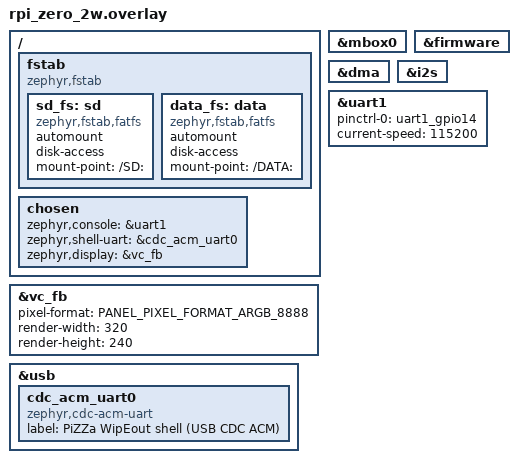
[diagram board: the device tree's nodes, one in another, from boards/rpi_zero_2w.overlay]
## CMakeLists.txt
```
# SPDX-License-Identifier: AGPL-3.0-or-later
#
# PiZZa -- WipEout demo. Stand-alone Zephyr application that links the
# phoboslab/wipeout-rewrite engine (software renderer) against the
# rpi_zero_2w board and presents 320x240 frames to the BCM2835
# VideoCore HDMI framebuffer via HVS hardware scaling.
#
# The engine source lives outside the PiZZa repo at
# ~/github/wipeout-rewrite. The port preserves the upstream tree --
# zero edits -- by:
#
#   1. Replacing src/render_software.c with our SMP-patched copy
#      (the upstream file is excluded from COMMON_SRC below).
#   2. Replacing src/platform_*.c with src/platform_zephyr.c.
#   3. --wrap=file_exists / file_load / file_store on the engine's
#      libc-backed utils.c so SD-card I/O lands on Zephyr's fs_*
#      with a /SD: prefix instead of POSIX fopen() (which is not
#      wired to FATFS in this image).
#
# The renderer is AGPL-3.0-or-later (matching wipeout-rewrite). The
# rest of PiZZa is Apache-2.0; this binary is AGPL by virtue of
# linking the engine, same model as the Jet demo.

cmake_minimum_required(VERSION 3.20.0)

find_package(Zephyr REQUIRED HINTS $ENV{ZEPHYR_BASE})
project(pizza-wipeout C)

# Pull in the sample usbd helper (sample_usbd_init_device + sample_usbd.h)
# the same way PizzaShell / Jet do. Only needed when the USB device
# stack is in the build; rpi_zero_2w turns it on.
if(CONFIG_USB_DEVICE_STACK_NEXT)
  include(${ZEPHYR_BASE}/samples/subsys/usb/common/common.cmake)
endif()

if(NOT DEFINED WIPEOUT_SRC_DIR)
  set(WIPEOUT_SRC_DIR "$ENV{HOME}/github/wipeout-rewrite/src")
endif()
if(NOT EXISTS "${WIPEOUT_SRC_DIR}/render_software.c")
  message(FATAL_ERROR
    "wipeout-rewrite sources not found at ${WIPEOUT_SRC_DIR}. Clone "
    "https://github.com/phoboslab/wipeout-rewrite and either keep it "
    "at ~/github/wipeout-rewrite or pass -DWIPEOUT_SRC_DIR=<path>.")
endif()

# Upstream engine sources (everything in src/ except the host platform
# backends and the original render_software.c -- we ship our own).
set(WIPEOUT_COMMON_SRC
  ${WIPEOUT_SRC_DIR}/utils.c
  ${WIPEOUT_SRC_DIR}/types.c
  ${WIPEOUT_SRC_DIR}/system.c
  ${WIPEOUT_SRC_DIR}/mem.c
  ${WIPEOUT_SRC_DIR}/input.c
  ${WIPEOUT_SRC_DIR}/wipeout/race.c
  ${WIPEOUT_SRC_DIR}/wipeout/camera.c
  ${WIPEOUT_SRC_DIR}/wipeout/object.c
  ${WIPEOUT_SRC_DIR}/wipeout/droid.c
  ${WIPEOUT_SRC_DIR}/wipeout/ui.c
  ${WIPEOUT_SRC_DIR}/wipeout/hud.c
  ${WIPEOUT_SRC_DIR}/wipeout/image.c
  ${WIPEOUT_SRC_DIR}/wipeout/game.c
  ${WIPEOUT_SRC_DIR}/wipeout/menu.c
  ${WIPEOUT_SRC_DIR}/wipeout/main_menu.c
  ${WIPEOUT_SRC_DIR}/wipeout/ingame_menus.c
  ${WIPEOUT_SRC_DIR}/wipeout/title.c
  ${WIPEOUT_SRC_DIR}/wipeout/intro.c
  ${WIPEOUT_SRC_DIR}/wipeout/scene.c
  ${WIPEOUT_SRC_DIR}/wipeout/ship.c
  ${WIPEOUT_SRC_DIR}/wipeout/ship_ai.c
  ${WIPEOUT_SRC_DIR}/wipeout/ship_player.c
  ${WIPEOUT_SRC_DIR}/wipeout/track.c
  ${WIPEOUT_SRC_DIR}/wipeout/weapon.c
  ${WIPEOUT_SRC_DIR}/wipeout/particle.c
  ${WIPEOUT_SRC_DIR}/wipeout/sfx.c
)

# Port sources. The rasteriser file is picked by Kconfig:
#   CONFIG_WIPEOUT_RENDERER_SMP (default) -> render_software_smp.c,
#     the upstream renderer with the band edit applied + gfx_parallel_run
#     wiring.
#   CONFIG_WIPEOUT_RENDERER_PIZZA -> render_software_pizza.c, the
#     Q16/RGB565 rewrite (scaffolding only; see
#     notes/wipeout_pizza_renderer_spec.md).
# gfx_parallel_zephyr.c is the persistent worker pool (band 0 on
# caller); platform_zephyr.c is the platform.h backend + the Zephyr
# main thread that drives the game loop; wipeout_glue.c wraps the
# engine's file_* helpers onto Zephyr fs_* + /SD: prefix.
if(CONFIG_WIPEOUT_RENDERER_PIZZA)
  set(WIPEOUT_RENDERER_SRC src/render_software_pizza.c)
else()
  set(WIPEOUT_RENDERER_SRC src/render_software_smp.c)
endif()

set(WIPEOUT_PORT_SRC
  ${WIPEOUT_RENDERER_SRC}
  src/gfx_parallel_zephyr.c
  src/platform_zephyr.c
  src/wipeout_glue.c
)

target_sources(app PRIVATE
  ${WIPEOUT_COMMON_SRC}
  ${WIPEOUT_PORT_SRC}
)

# Engine headers (#include "platform.h", "render.h", etc. without
# subdirs) and its bundled stb / pl_mpeg / qoa.
target_include_directories(app PRIVATE
  ${WIPEOUT_SRC_DIR}
  ${WIPEOUT_SRC_DIR}/libs
  src
)

target_compile_definitions(app PRIVATE
  RENDERER_SOFTWARE=1
)

# Loosen the warnings the engine trips with -Werror'ish defaults --
# upstream builds with -Wno-unused-variable and uses 1.0/255.0 idioms
# the compiler can't always prove safe.
target_compile_options(app PRIVATE
  -Wno-unused-variable
  -Wno-unused-but-set-variable
  -Wno-missing-braces
  -Wno-incompatible-pointer-types
)

# Redirect the engine's libc-backed file helpers to our Zephyr fs_*
# implementations. The originals stay in utils.c (unused at link time
# after wrapping) so no upstream edit is needed.
# PUBLIC, not PRIVATE: app is a Zephyr-built static lib, so PRIVATE
# link options never reach the final ELF link. PUBLIC propagates them
# through the target's INTERFACE_LINK_OPTIONS to the parent.
target_link_options(app PUBLIC
  -Wl,--wrap=file_exists
  -Wl,--wrap=file_load
  -Wl,--wrap=file_store
)
```

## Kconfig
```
# SPDX-License-Identifier: AGPL-3.0-or-later
#
# Pull in the SAMPLE_USBD_* options used by sample_usbd_init.c on
# boards that build the USB device stack. Same pattern PizzaShell /
# Jet use.

source "samples/subsys/usb/common/Kconfig.sample_usbd"

# Which port-side rasteriser to compile. The SMP renderer is the
# shipping renderer; the PiZZa renderer is the in-development
# Q16-RGB565 rewrite per notes/wipeout_pizza_renderer_spec.md.
# Today's builds keep the SMP default; flipping the gate swaps in
# the new file.
choice
	prompt "Wipeout software renderer backend"
	default WIPEOUT_RENDERER_SMP
	help
	  Selects which renderer source file the wipeout port compiles.
	  Both files implement the same render.h API; only one is
	  linked into a given build.

config WIPEOUT_RENDERER_SMP
	bool "Float ARGB_8888 SMP renderer (shipping)"
	help
	  render_software_smp.c -- the upstream phoboslab renderer plus
	  the PiZZa SMP band edits. Shipping configuration. ARGB_8888
	  framebuffer, float-per-pixel inner loop, scanline rasteriser.

config WIPEOUT_RENDERER_PIZZA
	bool "Q16 RGB565 PiZZa renderer (in development)"
	help
	  render_software_pizza.c -- Q16 fixed-point inner loop, RGB565
	  framebuffer, split RGBA5551 + RGBA4444 atlases, edge-function
	  rasteriser with five specialised fast paths. Targets ~3-5x
	  speedup over the SMP renderer on rpi_zero_2w.

	  Currently scaffolding only; enabling this option builds and
	  links but renders a black screen. See
	  notes/wipeout_pizza_renderer_spec.md for the phased plan.

endchoice

config WIPEOUT_USE_QPU_TRANSFORM
	bool "Use V3D QPU for vec3_transform_perspective (EMPIRICALLY SLOWER)"
	default n
	depends on WIPEOUT_RENDERER_SMP
	select BCM2835_V3D
	help
	  Offload the per-frame vec3_transform_perspective vertex math
	  from the A53 onto the BCM2710 V3D QPUs.

	  *** EMPIRICALLY NET-NEGATIVE -- DEFAULT OFF FOR A REASON ***

	  Standalone the QPU is ~9x faster per vertex than scalar
	  (48 ns vs 445 ns; see samples/drivers/bcm2835_v3d/vec3_xform).
	  But wipeout's renderer hands tris in 3-vert chunks, forcing
	  per-tri staging into V3D coherent memory + per-flush scatter/
	  gather. Measured via `wipeout bench all` (2026-06-09 on
	  rpi_zero_2w, NUM_QPUS=12, Normal-NC mapping + DSB barriers,
	  fused scatter, MIN_TRIS_FOR_KICK=64):

	    config                  scalar   QPU      delta
	    parallel-4  1000t / 1m   5753us  9205us   1.60x slower
	    parallel-4  3000t / 3m  14127us 24578us   1.74x slower
	    parallel-4  5000t / 3m  22589us 40088us   1.77x slower
	    parallel-4  7000t / 3m  30981us 55456us   1.79x slower

	  Per-tri the QPU integration costs ~3.5 us of staging +
	  finalize + scatter/gather overhead, displacing only ~1.3 us
	  of scalar transform (3 verts * 445 ns). The arithmetic does
	  not work out at this batching granularity -- no incremental
	  fix (drop AoS staging ~500 us/frame, bucket-on-stage
	  ~100 us/frame) closes the multi-millisecond gap.

	  Where the QPU genuinely wins on this silicon: single big-
	  batch kernels in the thousands+ of items (FFT, image filters,
	  small-model inference). Per-frame vertex transform in a
	  3-vert-at-a-time renderer is the wrong shape.

	  Enable only for code-path experimentation; the renderer falls
	  back to scalar for batches smaller than 64 triangles and on
	  QPU failure, so output is always correct (~16 ULP from
	  scalar, sub-pixel on a 240p framebuffer). The performance
	  cost is real and visible.

source "Kconfig.zephyr"
```

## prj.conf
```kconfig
# SPDX-License-Identifier: AGPL-3.0-or-later
#
# Common config for the PiZZa WipEout demo. Per-board overrides
# (display, USB, storage, SMP) live in boards/<board>.conf.

CONFIG_PRINTK=y
CONFIG_BOOT_BANNER=y

# Keep printk() synchronous so the engine's heavy boot-time logging
# (track scan, ship load) lands on the console even when the render
# loop is busy. Same reasoning as the Jet demo.
CONFIG_LOG_PRINTK=n

# picolibc's errno needs TLS. The cross-compile toolchain doesn't
# advertise TLS by default; opt in. Without this, errno writes off
# the main thread silently scribble through a wild TPIDRRO_EL0
# offset (the symptom is a Hard Fault on the first failing fs_open
# or fs_stat call).
CONFIG_TOOLCHAIN_CROSS_COMPILE_SUPPORTS_THREAD_LOCAL_STORAGE=y
CONFIG_THREAD_LOCAL_STORAGE=y

# Heap budgets. The engine uses its own bump allocator (mem.c) for
# assets but routes a handful of allocations through libc malloc:
# pl_mpeg's video frame buffer (skipped here -- no intro.mpeg),
# realloc() in render_software's depth buffer, qsort scratch. 1 MiB
# is plenty for the depth/zbuffer and per-flush sort scratch.
CONFIG_COMMON_LIBC_MALLOC_ARENA_SIZE=1048576

# Engine asset model. The bump arena lives in BSS at link time
# (mem.c MEM_HUNK_BYTES); we leave that at its upstream default but
# bump MAIN_STACK because game_init has deep call chains.
CONFIG_MAIN_STACK_SIZE=16384
CONFIG_FPU=y
CONFIG_STACK_SENTINEL=y
CONFIG_ASSERT=y
```

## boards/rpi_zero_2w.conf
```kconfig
# SPDX-License-Identifier: AGPL-3.0-or-later
#
# Raspberry Pi Zero 2 W (BCM2710, Cortex-A53, AArch64) -- WipEout demo.
# Console + logs on the mini-UART. USB CDC ACM shell for the `wipeout`
# command set (clock check, fps, frame capture). 4-core SMP enabled
# via the local Zephyr `dev` branch (smp-base..dev range -- the
# SOC_PER_CORE_INIT_HOOK gate plus the BCM2836 mailbox-0 sched-IPI
# driver). `wipeout flush parallel 4 64` runs bands 1..3 on their
# own cpus.

CONFIG_BOOT_DELAY=200

# 4-core SMP. Brings up cpu@1..3 via spin-table secondary release;
# scheduler IPI runs over the BCM2836 per-core mailbox 0. Peripheral
# and GPU interrupts stay on core 0 -- fine for the renderer because
# workers wait on semaphores from cpu 0 and do no peripheral I/O.
# Enables k_thread_cpu_pin() so gfx_parallel_zephyr.c's pin path
# actually puts bands 1..3 on cpus 1..3.
CONFIG_SMP=y
CONFIG_MP_MAX_NUM_CPUS=4
CONFIG_SCHED_CPU_MASK=y
CONFIG_SCHED_CPU_MASK_PIN_ONLY=y
CONFIG_PM_CPU_OPS=y
CONFIG_PM_CPU_OPS_SPINTABLE=y
# FPU_SHARING rides the Cortex-A Kconfig imply: the FPU-flush IPI runs
# as mailbox-0 bit 1 next to the scheduler IPI (zephyr dev a036e77bc0f),
# so FPU context migrates safely between cores. This is the gate for
# NEON in the rasteriser -- V registers alias the FP register file.

# VC mailbox + firmware (framebuffer alloc chain, ARM clock readback,
# die temp).
CONFIG_RASPBERRYPI_FIRMWARE=y
CONFIG_HWINFO=y
CONFIG_SENSOR=y

# HDMI display via VC firmware FB. ARGB_8888 (depth 32) so the engine's
# rgba_t buffer maps 1:1 onto a 32-bit FB word (modulo the R/B swap
# we do at present time -- see platform_zephyr.c). Pair with the
# render-width / render-height overlay for HVS 320x240 -> monitor
# scaling.
CONFIG_DISPLAY=y
CONFIG_BCM2835_FB=y

# BCM2835 DMA -- the FB driver claims a free channel at init for the
# backbuffer->fb blit. Hides the present memcpy off the CPU.
CONFIG_DMA=y
CONFIG_DMA_BCM2835=y

# Storage stack on the external microSD slot (SDHost). Wipeout assets
# (~150 MB after `wipeout-data-v01.zip` extraction) live at
# /SD:/wipeout/. CONFIG_FILE_SYSTEM_MKFS stays OFF -- a failed mount
# must not erase the user's card.
CONFIG_DISK_ACCESS=y
CONFIG_DISK_DRIVERS=y
CONFIG_SDMMC_SUBSYS=y
CONFIG_FILE_SYSTEM=y
CONFIG_FAT_FILESYSTEM_ELM=y
CONFIG_FS_FATFS_LFN=y
CONFIG_FS_FATFS_FSTAB_AUTOMOUNT=y
CONFIG_FILE_SYSTEM_MKFS=n
CONFIG_FS_FATFS_MOUNT_MKFS=n

# Multi-partition support. The PINN-imaged SD has a RECOVERY FAT at
# partition 1 (Pi firmware, dtbs, our kernel.img -- bootloader-visible
# only, no room for assets). We mount that as /SD: AND also bind a
# second FAT partition (partition 2, manually added from the ~31 GiB
# of unallocated tail on the card) as /DATA: for the wipeout/ asset
# tree. Both logical volumes share the one physical SDHost disk;
# FatFs reads the MBR to locate each partition's LBA range via the
# app-side VolToPart[] table in wipeout_glue.c.
CONFIG_FS_FATFS_MULTI_PARTITION=y
CONFIG_FS_FATFS_CUSTOM_MOUNT_POINT_COUNT=2
CONFIG_FS_FATFS_CUSTOM_MOUNT_POINTS="SD,DATA"

# USB device stack -- CDC ACM as the shell endpoint, matching the
# rest of PiZZa. Boards with USBD need the sample helper.
CONFIG_USB_DEVICE_STACK_NEXT=y
CONFIG_UDC_DWC2=y
CONFIG_UDC_DWC2_DMA=n
CONFIG_SERIAL=y
CONFIG_USBD_CDC_ACM_CLASS=y
CONFIG_CDC_ACM_SERIAL_INITIALIZE_AT_BOOT=n
CONFIG_SAMPLE_USBD_PRODUCT="PiZZa WipEout demo -- rpi_zero_2w"
CONFIG_SAMPLE_USBD_MANUFACTURER="jetpax/PiZZa"
CONFIG_SAMPLE_USBD_PID=0xCAFE
CONFIG_USBD_THREAD_STACK_SIZE=4096
CONFIG_UDC_DWC2_STACK_SIZE=4096

# Interactive shell over the USB CDC line (boot logs stay on the
# mini-UART). The `wipeout` subcommand set is registered from
# platform_zephyr.c.
CONFIG_SHELL=y
CONFIG_SHELL_BACKEND_SERIAL=y
CONFIG_KERNEL_SHELL=y
CONFIG_SHELL_STACK_SIZE=8192
CONFIG_SHELL_VT100_COMMANDS=y
CONFIG_SHELL_HISTORY=y
CONFIG_SHELL_TAB=y
CONFIG_SHELL_LOG_BACKEND=n

# Logging on the board console (mini-UART), off the shell prompt.
CONFIG_LOG=y
CONFIG_LOG_BUFFER_SIZE=16384
CONFIG_LOG_BACKEND_UART=y
CONFIG_LOG_MODE_DEFERRED=y
CONFIG_USBD_CDC_ACM_LOG_LEVEL_WRN=y
CONFIG_USBD_LOG_LEVEL_INF=y
CONFIG_UDC_DRIVER_LOG_LEVEL_WRN=y
```

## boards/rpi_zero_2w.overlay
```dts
/*
 * SPDX-License-Identifier: AGPL-3.0-or-later
 *
 * PiZZa WipEout demo overlay for rpi_zero_2w.
 *
 *   - &mbox0 + &firmware: VC mailbox + property tags (FB alloc,
 *     clock readback, temp).
 *   - &vc_fb: HDMI framebuffer at the monitor's native scanout
 *     resolution; the engine paints into a 320x240 virtual
 *     framebuffer and the VideoCore HVS hardware scaler upscales it
 *     to the cable on the fly. Picks the PSX-style nostalgic look
 *     and keeps per-frame write bandwidth at 300 KiB instead of
 *     ~7 MiB at HDMI native.
 *   - &dma: BCM2835 DMA controller for the bcm2835_fb backbuffer
 *     blit (fast path).
 *   - &usb + cdc_acm child: USB CDC ACM as the interactive shell
 *     endpoint, same shape as PizzaShell.
 *   - SD fstab at /SD: (FATFS) for wipeout asset loading.
 *   - mini-UART (uart1) as console + LOG_* target, matching the
 *     PiZZa convention.
 */

#include <zephyr/dt-bindings/display/panel.h>

&mbox0 {
	status = "okay";
};

&firmware {
	status = "okay";
};

/*
 * BCM2835 DMA controller -- bcm2835_fb requests a free channel at
 * init for its backbuffer->fb blit. No DT wiring on the FB side.
 */
&dma {
	status = "okay";
};

&vc_fb {
	/* No width / height: driver reads VC's EDID-negotiated scanout
	 * mode at boot (typically 1824x984 or whatever the monitor
	 * reports).
	 *
	 * render-width / render-height pin the virtual framebuffer the
	 * ARM side paints into. 320 x 240 = 76800 px = 300 KiB at 32 bpp.
	 * 320 * 4 = 1280 bytes = 64-byte aligned, so VC returns pitch ==
	 * row_bytes (no padding) and the FB driver's contiguous-DMA fast
	 * path engages. HVS scales 320x240 -> monitor native at 0 ARM
	 * cost.
	 */
	pixel-format = <PANEL_PIXEL_FORMAT_ARGB_8888>;
	render-width = <320>;
	render-height = <240>;
	status = "okay";
};

&i2s {
	/* No audio yet -- left enabled in case M7 lands later. */
	status = "okay";
};

/*
 * Auto-mount the external microSD slot as FAT at /SD: (FATFS volume
 * convention: the path after the leading '/' is the disk-access disk
 * name). The board DTS registers the disk as "SD". The user extracts
 * wipeout-data-v01.zip to /SD:/wipeout/ before flashing.
 *
 * Format-on-mount-fail safety: CONFIG_FILE_SYSTEM_MKFS and
 * CONFIG_FS_FATFS_MOUNT_MKFS are both off in boards/rpi_zero_2w.conf,
 * so a failed mount cannot accidentally erase the user's SD card.
 */
/ {
	fstab {
		compatible = "zephyr,fstab";

		/* PINN RECOVERY (FAT) -- Pi firmware + dtbs + kernel.img.
		 * Save data (small) writes go here. Mount string "/SD:"
		 * matches CONFIG_FS_FATFS_CUSTOM_MOUNT_POINTS index 0,
		 * which VolToPart[] maps to physical drive 0, partition 1.
		 */
		sd_fs: sd {
			compatible = "zephyr,fstab,fatfs";
			automount;
			disk-access;
			mount-point = "/SD:";
		};

		/* User-created FAT partition (typically partition 3 on the
		 * PINN card) holding the wipeout/ asset tree extracted from
		 * wipeout-data-v01.zip. Mount string "/DATA:" matches
		 * CONFIG_FS_FATFS_CUSTOM_MOUNT_POINTS index 1, which
		 * VolToPart[] maps to physical drive 0, partition 3. Same
		 * physical SDHost as /SD: -- the partition split happens
		 * inside FatFs by reading the MBR.
		 */
		data_fs: data {
			compatible = "zephyr,fstab,fatfs";
			automount;
			disk-access;
			mount-point = "/DATA:";
		};
	};
};

&usb {
	status = "okay";

	cdc_acm_uart0: cdc_acm_uart0 {
		compatible = "zephyr,cdc-acm-uart";
		label = "PiZZa WipEout shell (USB CDC ACM)";
	};
};

/ {
	chosen {
		/* Boot logs + LOG_* on the mini-UART (uart1) at 115200 --
		 * needs config.txt `enable_uart=1`, NOT `dtoverlay=disable-bt`.
		 * Interactive shell on USB CDC ACM. HDMI is the engine
		 * display target (auto-detected through DT_HAS_CHOSEN by
		 * the FB driver).
		 */
		zephyr,console = &uart1;
		zephyr,shell-uart = &cdc_acm_uart0;
		zephyr,display = &vc_fb;
	};
};

/* Mini-UART (uart1) console setup. Same stanza PizzaShell carries --
 * the board DTS now defaults to PL011 @ 1 Mbaud, but PiZZa boards
 * keep the historical mini-UART path so a stock config.txt with
 * `enable_uart=1` (no disable-bt overlay) just works.
 */
&uart1 {
	pinctrl-names = "default";
	pinctrl-0 = <&uart1_gpio14>;
	status = "okay";
	current-speed = <115200>;
};
```

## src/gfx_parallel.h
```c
/* SPDX-License-Identifier: AGPL-3.0-or-later
 *
 * Persistent band-parallel barrier for the PiZZa software renderer.
 * Verified bit-identical to serial in simulation (4 bands; 0 / 76 800
 * pixels differ) -- the property that breaks in naive parallel
 * rasterizer rewrites holds: y-band ownership of disjoint framebuffer
 * + depth rows is lock-free and order-preserving because tris are
 * z-sorted ONCE on the caller before fan-out.
 *
 * Backend split:
 *   - Host (sim): pthreads.
 *   - Zephyr / on-board: persistent pool of CONFIG threads pinned to
 *     cores 1..N-1 (CONFIG_SMP + CONFIG_SCHED_CPU_MASK), with the
 *     caller (game thread) executing band 0 itself. Without SMP
 *     enabled at the board level, all bands fall back onto the calling
 *     core -- the band split still produces correct output but the
 *     workers contend for CPU0 and the speedup is <= 1.
 */
#ifndef GFX_PARALLEL_H
#define GFX_PARALLEL_H

#include <stdint.h>

#define GFX_PARALLEL_MAX_BANDS 4

/* Runs fn(ctx, band_index) on `nbands` workers and blocks until all
 * finish. Caller thread runs band 0 inline.
 */
typedef void (*gfx_band_fn)(void *ctx, int band);

void gfx_parallel_init(int nbands);
void gfx_parallel_run(gfx_band_fn fn, void *ctx, int nbands);

/* True iff Zephyr was built with CONFIG_SMP and at least 2 CPUs are
 * runnable. Set inside gfx_parallel_init() so the renderer can pick
 * the serial flush when SMP is absent without burning a barrier
 * round-trip.
 */
int gfx_parallel_smp_active(void);

#endif /* GFX_PARALLEL_H */
```

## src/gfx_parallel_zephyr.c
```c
/* SPDX-License-Identifier: AGPL-3.0-or-later
 *
 * Zephyr backend for the band-parallel barrier. Persistent worker
 * pool: bands 1..N-1 each have a dedicated CONFIG thread parked on a
 * "go" semaphore between flushes; band 0 runs on the caller (game
 * thread).
 *
 * The cpu_pin call below is guarded on CONFIG_SCHED_CPU_MASK. Without
 * it (the rpi_zero_2w default today) the workers compete with the
 * caller for CPU0 cooperatively -- the band split still produces a
 * correct frame but speedup vs serial is <= 1. The path is here so
 * the renderer code is single-shape across SMP and UP; flip the gate
 * in render_software_smp.c (or via shell `wipeout flush parallel`)
 * to actually exercise it when SMP lands.
 */

#include <zephyr/kernel.h>
#include "gfx_parallel.h"

#define WORKER_STACK 8192

static struct k_thread       threads[GFX_PARALLEL_MAX_BANDS];
static K_THREAD_STACK_ARRAY_DEFINE(stacks, GFX_PARALLEL_MAX_BANDS, WORKER_STACK);
static struct k_sem          go[GFX_PARALLEL_MAX_BANDS];
static struct k_sem          done;
static gfx_band_fn           cur_fn;
static void                 *cur_ctx;
static int                   n_bands;
static int                   smp_active;

static void worker(void *p0, void *p1, void *p2)
{
	int band = (int)(intptr_t)p0;

	ARG_UNUSED(p1);
	ARG_UNUSED(p2);

	for (;;) {
		k_sem_take(&go[band], K_FOREVER);
		cur_fn(cur_ctx, band);
		k_sem_give(&done);
	}
}

void gfx_parallel_init(int nbands)
{
	if (nbands < 1) {
		nbands = 1;
	}
	if (nbands > GFX_PARALLEL_MAX_BANDS) {
		nbands = GFX_PARALLEL_MAX_BANDS;
	}
	n_bands = nbands;
	k_sem_init(&done, 0, nbands);

#if defined(CONFIG_SMP) && defined(CONFIG_SCHED_CPU_MASK)
	smp_active = (arch_num_cpus() > 1) ? 1 : 0;
#else
	smp_active = 0;
#endif

	/* Band 0 runs on the calling thread; spawn workers for bands
	 * 1..n-1 and try to pin them, one per core. With SMP off the
	 * pin is a no-op and the workers serialize on CPU0; with SMP
	 * on, each band runs lock-free on its own core.
	 */
	for (int b = 1; b < nbands; b++) {
		k_sem_init(&go[b], 0, 1);
		k_tid_t t = k_thread_create(&threads[b], stacks[b], WORKER_STACK,
					    worker, (void *)(intptr_t)b, NULL, NULL,
					    K_PRIO_COOP(5), 0, K_NO_WAIT);
		k_thread_name_set(t, "gfx_band");
#if defined(CONFIG_SMP) && defined(CONFIG_SCHED_CPU_MASK)
		(void)k_thread_cpu_pin(t, b);
#endif
	}
}

void gfx_parallel_run(gfx_band_fn fn, void *ctx, int nbands)
{
	if (nbands <= 1) {
		fn(ctx, 0);
		return;
	}
	if (nbands > n_bands) {
		nbands = n_bands;
	}
	cur_fn = fn;
	cur_ctx = ctx;
	for (int b = 1; b < nbands; b++) {
		k_sem_give(&go[b]);
	}
	fn(ctx, 0);
	for (int b = 1; b < nbands; b++) {
		k_sem_take(&done, K_FOREVER);
	}
}

int gfx_parallel_smp_active(void)
{
	return smp_active;
}
```

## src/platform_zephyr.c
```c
/* SPDX-License-Identifier: AGPL-3.0-or-later
 *
 * PiZZa WipEout port -- platform.h backend + Zephyr boot wiring.
 *
 * Architecture (locked):
 *   - RENDERER=SOFTWARE (pure C); engine renders into a 320x240
 *     rgba_t backbuffer in cached RAM.
 *   - HVS hardware scaling: vc_fb DT exposes render-width=320,
 *     render-height=240. VC upscales every frame to the monitor's
 *     EDID-negotiated native mode at zero ARM cost.
 *   - Present: byte-swap-in-place (engine rgba_t bytes are R,G,B,A;
 *     VC ARGB_8888 expects B,G,R,A in memory) then async DMA blit.
 *   - SD card auto-mounted at /SD: (FATFS); assets at /SD:/wipeout/.
 *   - Audio + BT HID out of scope this milestone.
 *
 * The Zephyr boot model is platform-calls-you: main() does board
 * bring-up, then either runs the game loop on the main thread or
 * (here) spawns a dedicated render thread. The shell's USB CDC
 * service keeps running on the system workqueue; the render thread
 * yields once per frame so the shell stays responsive.
 */

#include <zephyr/kernel.h>
#include <zephyr/device.h>
#include <zephyr/devicetree.h>
#include <zephyr/drivers/display.h>
#include <zephyr/drivers/display/bcm2835_fb.h>
#include <zephyr/shell/shell.h>
#include <zephyr/sys/printk.h>
#include <zephyr/logging/log.h>
#include <zephyr/fs/fs.h>
#include <stdint.h>
#include <stdio.h>
#include <string.h>

#include <rpi_fw.h>

#if IS_ENABLED(CONFIG_USB_DEVICE_STACK_NEXT)
#include <zephyr/usb/usbd.h>
#include <sample_usbd.h>
#endif

/* Engine headers. types.h pulls in stdint/math; platform.h declares
 * the 12-function contract this file implements; render.h gives us
 * vec2i_t, render_resolution_t, render_set_resolution, etc.; system.h
 * the system_init/system_update entry points.
 */
#include "types.h"
#include "platform.h"
#include "render.h"
#include "input.h"
#include "system.h"

LOG_MODULE_REGISTER(pizza_wipeout, LOG_LEVEL_INF);

/* Renderer parallel-flush knob (defined in render_software_smp.c).
 * Not in render.h -- it's a port-private switch the M5 benchmark
 * shell command toggles.
 */
extern void render_software_set_parallel(int enabled, int bands, int threshold);
extern int  render_software_get_parallel_bands(void);

/* ------------------------------------------------------------------ *
 *  Display state
 * ------------------------------------------------------------------ */

#define PIZZA_W 320
#define PIZZA_H 240
#define PIZZA_PX (PIZZA_W * PIZZA_H)

/* 64-byte aligned: DMA fast path + cache-line clean range. Size is
 * exactly 4800 cache lines so sys_cache_data_flush_range covers
 * nothing outside this buffer.
 */
static rgba_t pizza_backbuf[PIZZA_PX] __aligned(64);

static const struct device *pizza_display;
static int pizza_display_ready;

/* ------------------------------------------------------------------ *
 *  platform.h timing / window backend
 * ------------------------------------------------------------------ */

double platform_now(void)
{
	return (double)k_uptime_get() / 1000.0;
}

vec2i_t platform_screen_size(void)
{
	return (vec2i_t){PIZZA_W, PIZZA_H};
}

bool platform_get_fullscreen(void) { return true; }
void platform_set_fullscreen(bool on) { (void)on; }

void platform_exit(void)
{
	printk("[wipeout] platform_exit -- halting\n");
	k_fatal_halt(0);
}

/* ------------------------------------------------------------------ *
 *  platform.h audio backend (silent stub)
 * ------------------------------------------------------------------ */

static void (*pizza_audio_cb)(float *, uint32_t);

void platform_set_audio_mix_cb(void (*cb)(float *, uint32_t))
{
	pizza_audio_cb = cb;
	/* TODO(board): drive cb from an I2S DMA buffer-complete handler. */
}

/* ------------------------------------------------------------------ *
 *  platform.h screenbuffer backend (software renderer)
 *
 *  render_software calls this once per render_frame_prepare() to
 *  grab the destination pointer and byte-pitch. We hand back our
 *  cached rgba_t backbuffer; bytes are R,G,B,A in memory. The engine
 *  paints into it serial or banded (see render_software_smp.c).
 * ------------------------------------------------------------------ */

rgba_t *platform_get_screenbuffer(int32_t *pitch_bytes)
{
	*pitch_bytes = (int32_t)(PIZZA_W * sizeof(rgba_t));
	return pizza_backbuf;
}

/* ------------------------------------------------------------------ *
 *  platform.h asset backend
 *
 *  platform_open_asset returns a stdio FILE*; this firmware does NOT
 *  wire fopen to FATFS (no POSIX fs shim), so we return NULL. The
 *  only direct callers are sfx music streaming (graceful: empty
 *  music) and intro.mpeg (graceful: skips straight to TITLE).
 *
 *  platform_load_asset / platform_load_userdata route through the
 *  engine's file_load helper, which is --wrap'd to our fs_*-backed
 *  __wrap_file_load in wipeout_glue.c.
 * ------------------------------------------------------------------ */

#define PATH_PREFIX_ASSETS  ""              /* engine asks for "wipeout/foo" already */
#define PATH_PREFIX_USERDATA "userdata/"    /* save.dat etc. */

FILE *platform_open_asset(const char *name, const char *mode)
{
	(void)name; (void)mode;
	/* Streaming I/O not supported in this image. Callers that need
	 * a FILE* (sfx_music_open, intro.mpeg) handle NULL gracefully.
	 */
	return NULL;
}

uint8_t *platform_load_asset(const char *name, uint32_t *len)
{
	extern uint8_t *file_load(const char *path, uint32_t *bytes_read);
	return file_load(name, len);
}

uint8_t *platform_load_userdata(const char *name, uint32_t *len)
{
	extern bool file_exists(const char *path);
	extern uint8_t *file_load(const char *path, uint32_t *bytes_read);
	char path[128];

	snprintf(path, sizeof(path), "%s%s", PATH_PREFIX_USERDATA, name);
	if (!file_exists(path)) {
		*len = 0;
		return NULL;
	}
	return file_load(path, len);
}

uint32_t platform_store_userdata(const char *name, void *bytes, int32_t len)
{
	extern uint32_t file_store(const char *path, void *bytes, int32_t len);
	char path[128];

	snprintf(path, sizeof(path), "%s%s", PATH_PREFIX_USERDATA, name);
	return file_store(path, bytes, len);
}

/* ------------------------------------------------------------------ *
 *  USB CDC bring-up (boards with the USB device stack)
 * ------------------------------------------------------------------ */

#if IS_ENABLED(CONFIG_USB_DEVICE_STACK_NEXT)
static int pizza_usb_start(void)
{
	struct usbd_context *usbd = sample_usbd_init_device(NULL);

	if (usbd == NULL) {
		printk("[wipeout] sample_usbd_init_device failed\n");
		return -ENODEV;
	}
	if (!usbd_can_detect_vbus(usbd)) {
		int err = usbd_enable(usbd);
		if (err) {
			printk("[wipeout] usbd_enable failed: %d\n", err);
			return err;
		}
	}
	return 0;
}
/*
 * Bring CDC up at APPLICATION init, not from main(). The display + FATFS
 * (microSD) + SMP bring-up that runs during main() add enough latency
 * to push usbd_enable past macOS's USB enumeration retry window when
 * the mini-UART is connected at boot, which silently kills CDC on the
 * host side until the next replug. Running at APPLICATION captures
 * the enumeration window early; the rest of main() then runs while
 * the host completes descriptor exchange in parallel.
 */
SYS_INIT(pizza_usb_start, APPLICATION, CONFIG_APPLICATION_INIT_PRIORITY);
#else
static inline int pizza_usb_start(void) { return 0; }
#endif

/* ------------------------------------------------------------------ *
 *  Present: byte-swap-in-place + async DMA blit
 *
 *  Engine rgba_t bytes (R,G,B,A) don't match the VC ARGB_8888 layout
 *  (memory B,G,R,A). Swap byte[0] <-> byte[2] in the backbuffer; the
 *  next render_frame_prepare() clears the whole buffer, so the
 *  "wrong-order" state only persists from end-of-frame N until the
 *  start of frame N+1, never read by the renderer.
 *
 *  Pixel-loop walks rgba_t* (a 4-byte struct); on aarch64 with the
 *  buffer __aligned(64) the compiler vectorises this into LDR W /
 *  REV W / STR W pairs at ~one cycle per pixel.
 *
 *  Returns the wait+blit cycles for fps accounting.
 * ------------------------------------------------------------------ */

static void pizza_byteswap_inplace(rgba_t *buf, uint32_t pixels)
{
	uint8_t *b = (uint8_t *)buf;
	for (uint32_t i = 0; i < pixels; i++) {
		uint8_t r = b[0];
		b[0] = b[2];
		b[2] = r;
		b += 4;
	}
}

static int pizza_present(void)
{
	struct display_buffer_descriptor desc = {
		.buf_size = sizeof(pizza_backbuf),
		.width    = PIZZA_W,
		.height   = PIZZA_H,
		.pitch    = PIZZA_W,
		.frame_incomplete = false,
	};

	pizza_byteswap_inplace(pizza_backbuf, PIZZA_PX);

	/* display_write is synchronous: DMA fast path engages when
	 * width==virt_width and pitch==width (the case here -- 320 x 4 =
	 * 1280 is 64-byte aligned and VC returns no padding); the driver
	 * flushes the source cache range internally before kicking.
	 *
	 * We use the sync API instead of bcm2835_fb_write_async because
	 * we have a single backbuffer: an async kick from frame N would
	 * still be reading pizza_backbuf when frame N+1's
	 * render_frame_prepare() starts clearing it. Adding a second
	 * backbuffer would lift this restriction and let frame time
	 * approach max(render, blit) -- a clean future optimisation but
	 * not load-bearing for M4 (render dwarfs blit at 240p).
	 */
	return display_write(pizza_display, 0, 0, &desc, pizza_backbuf);
}

/* ------------------------------------------------------------------ *
 *  Game loop -- runs on a dedicated thread, owns the present step
 *
 *  system_update() internally calls render_frame_prepare ->
 *  game_update -> render_frame_end -> render_flush, leaving the
 *  finished frame in pizza_backbuf. We present afterwards.
 *
 *  fps and per-phase cycle counts are tracked here; the `wipeout`
 *  shell commands read these.
 * ------------------------------------------------------------------ */

#define GAME_STACK_SIZE 32768

K_THREAD_STACK_DEFINE(pizza_game_stack, GAME_STACK_SIZE);
static struct k_thread pizza_game_thread;

static volatile uint32_t pizza_fps_x100;   /* fps * 100, sampled every 1s */
static volatile uint32_t pizza_us_update;  /* avg per-frame system_update us */
static volatile uint32_t pizza_us_present; /* avg per-frame present us */
static volatile uint32_t pizza_frames_total;
static volatile uint32_t pizza_last_tris;

/* Flag set by shell `wipeout capture` to ask the loop to dump the
 * next finished frame to /SD:/wipeout-frame.ppm. Cleared after dump.
 */
static volatile int pizza_capture_requested;

extern int pizza_capture_frame(const rgba_t *buf, int w, int h);

extern void pizza_sd_diag(void);

static void pizza_game_loop(void *p1, void *p2, void *p3)
{
	ARG_UNUSED(p1);
	ARG_UNUSED(p2);
	ARG_UNUSED(p3);

	printk("[wipeout] game thread up; SD diagnostic:\n");
	pizza_sd_diag();
	printk("[wipeout] calling system_init\n");
	system_init();
	printk("[wipeout] system_init OK; entering render loop\n");

	int64_t fps_window_start = k_uptime_get();
	uint32_t frames_in_window = 0;
	uint64_t cyc_update = 0;
	uint64_t cyc_present = 0;
	const uint64_t cycles_per_sec = sys_clock_hw_cycles_per_sec();

	for (;;) {
		uint32_t c0 = k_cycle_get_32();
		system_update();
		uint32_t c1 = k_cycle_get_32();

		(void)pizza_present();
		uint32_t c2 = k_cycle_get_32();

		/* Capture happens BEFORE the next render_frame_prepare()
		 * clears the buffer. Note pizza_backbuf is currently
		 * byte-swapped (B,G,R,A); the capture helper inverts.
		 */
		if (pizza_capture_requested) {
			pizza_capture_requested = 0;
			pizza_capture_frame(pizza_backbuf, PIZZA_W, PIZZA_H);
		}

		cyc_update  += (uint32_t)(c1 - c0);
		cyc_present += (uint32_t)(c2 - c1);
		frames_in_window++;
		pizza_frames_total++;

		const render_stats_t *st = render_frame_get_stats();
		if (st) {
			pizza_last_tris = st->num_tris;
		}

		const int64_t now = k_uptime_get();
		const int64_t elapsed_ms = now - fps_window_start;
		if (elapsed_ms >= 1000) {
			pizza_fps_x100 =
				(uint32_t)((int64_t)frames_in_window * 100000 / elapsed_ms);
			pizza_us_update =
				(uint32_t)((cyc_update * 1000000U) /
					   (cycles_per_sec * frames_in_window));
			pizza_us_present =
				(uint32_t)((cyc_present * 1000000U) /
					   (cycles_per_sec * frames_in_window));
			printk("[wipeout] %u.%02u fps  update=%u us  present=%u us  tris=%u  bands=%d\n",
			       pizza_fps_x100 / 100, pizza_fps_x100 % 100,
			       pizza_us_update, pizza_us_present,
			       pizza_last_tris,
			       render_software_get_parallel_bands());
			fps_window_start = now;
			frames_in_window = 0;
			cyc_update = cyc_present = 0;
		}

		/* Cooperate with the shell + USBD + log thread. */
		k_yield();
	}
}

/* ------------------------------------------------------------------ *
 *  Shell command set: `wipeout <sub>`
 * ------------------------------------------------------------------ */

#define VC_CLOCK_ID_ARM  3U

static int cmd_wipeout_fps(const struct shell *sh, size_t argc, char **argv)
{
	ARG_UNUSED(argc); ARG_UNUSED(argv);
	shell_print(sh, "fps=%u.%02u  update=%u us  present=%u us",
		    pizza_fps_x100 / 100, pizza_fps_x100 % 100,
		    pizza_us_update, pizza_us_present);
	shell_print(sh, "tris/frame=%u  bands=%d  frames_total=%u",
		    pizza_last_tris,
		    render_software_get_parallel_bands(),
		    pizza_frames_total);
	return 0;
}

static int cmd_wipeout_clock(const struct shell *sh, size_t argc, char **argv)
{
	ARG_UNUSED(argc); ARG_UNUSED(argv);
	const struct device *fw = DEVICE_DT_GET_ONE(raspberrypi_bcm283x_firmware);
	uint32_t cur[2] = {VC_CLOCK_ID_ARM, 0};
	uint32_t max[2] = {VC_CLOCK_ID_ARM, 0};

	if (!device_is_ready(fw)) {
		shell_error(sh, "rpi_fw device not ready");
		return -ENODEV;
	}
	int e1 = rpi_fw_transfer(fw, RPI_FW_TAG_GET_CLOCK_RATE, cur, sizeof(cur));
	int e2 = rpi_fw_transfer(fw, RPI_FW_TAG_GET_MAX_CLOCK_RATE, max, sizeof(max));

	if (e1 < 0 || e2 < 0) {
		shell_error(sh, "rpi_fw clock query failed: cur=%d max=%d", e1, e2);
		return -EIO;
	}
	shell_print(sh, "ARM clock: cur=%u Hz  max=%u Hz", cur[1], max[1]);
	if (cur[1] < 900000000U) {
		shell_warn(sh, "ARM clock is below 900 MHz (got %u Hz). Set "
				"`arm_freq=1000` + `force_turbo=1` in config.txt to "
				"pin it at 1 GHz.", cur[1]);
	}
	return 0;
}

static int cmd_wipeout_flush(const struct shell *sh, size_t argc, char **argv)
{
	int bands = 4;
	int threshold = 64;

	if (argc < 2) {
		shell_print(sh, "usage: wipeout flush serial|parallel [bands] [threshold]");
		return -EINVAL;
	}
	if (strcmp(argv[1], "serial") == 0) {
		render_software_set_parallel(0, 1, 1);
		shell_print(sh, "render: serial flush");
		return 0;
	}
	if (strcmp(argv[1], "parallel") == 0) {
		extern int gfx_parallel_smp_active(void);

		if (argc >= 3) bands = atoi(argv[2]);
		if (argc >= 4) threshold = atoi(argv[3]);
		render_software_set_parallel(1, bands, threshold);
		shell_print(sh, "render: parallel flush bands=%d threshold=%d  (cpus=%u, smp_active=%d)",
			    bands, threshold,
			    (unsigned)arch_num_cpus(),
			    gfx_parallel_smp_active());
		if (!gfx_parallel_smp_active()) {
			shell_warn(sh, "SMP inactive: secondary cores didn't come up "
					"or build is UP. Workers will share CPU0 and pay "
					"barrier cost for no parallelism.");
		}
		return 0;
	}
	shell_error(sh, "unknown subcommand '%s'", argv[1]);
	return -EINVAL;
}

static int cmd_wipeout_capture(const struct shell *sh, size_t argc, char **argv)
{
	ARG_UNUSED(argc); ARG_UNUSED(argv);
	if (pizza_capture_requested) {
		shell_print(sh, "capture already pending");
		return 0;
	}
	pizza_capture_requested = 1;
	shell_print(sh, "capture armed: next frame -> /SD:/wipeout-frame.ppm");
	return 0;
}

static int cmd_wipeout_display(const struct shell *sh, size_t argc, char **argv)
{
	ARG_UNUSED(argc); ARG_UNUSED(argv);
	if (!pizza_display) {
		shell_error(sh, "display device unset");
		return -ENODEV;
	}
	struct display_capabilities caps;

	display_get_capabilities(pizza_display, &caps);
	shell_print(sh, "display: %ux%u px  fmt=0x%x  ready=%d",
		    caps.x_resolution, caps.y_resolution,
		    (unsigned)caps.current_pixel_format,
		    pizza_display_ready);
	return 0;
}

static int cmd_wipeout_smp(const struct shell *sh, size_t argc, char **argv)
{
	extern int gfx_parallel_smp_active(void);

	ARG_UNUSED(argc); ARG_UNUSED(argv);
	shell_print(sh, "CONFIG_SMP=%s  MP_MAX_NUM_CPUS=%d",
#ifdef CONFIG_SMP
		    "y",
#else
		    "n",
#endif
		    CONFIG_MP_MAX_NUM_CPUS);
	shell_print(sh, "arch_num_cpus() = %u  (cores ONLINE at runtime)",
		    (unsigned)arch_num_cpus());
	shell_print(sh, "gfx_parallel_smp_active() = %d  (renderer's worker-pool view)",
		    gfx_parallel_smp_active());
	return 0;
}

SHELL_STATIC_SUBCMD_SET_CREATE(sub_wipeout,
	SHELL_CMD(fps,     NULL, "Sampled fps + per-phase us",          cmd_wipeout_fps),
	SHELL_CMD(clock,   NULL, "VC ARM clock cur/max (Hz)",            cmd_wipeout_clock),
	SHELL_CMD(flush,   NULL, "serial | parallel [bands] [threshold]", cmd_wipeout_flush),
	SHELL_CMD(capture, NULL, "Dump next frame to /DATA:/wipeout-frame.ppm", cmd_wipeout_capture),
	SHELL_CMD(display, NULL, "Display capabilities + ready state",   cmd_wipeout_display),
	SHELL_CMD(smp,     NULL, "SMP build + runtime status",           cmd_wipeout_smp),
	SHELL_SUBCMD_SET_END
);
SHELL_CMD_REGISTER(wipeout, &sub_wipeout, "PiZZa WipEout demo control", NULL);

/* ------------------------------------------------------------------ *
 *  Zephyr main()
 * ------------------------------------------------------------------ */

int main(void)
{
	printk("\n[wipeout] PiZZa WipEout demo -- rpi_zero_2w SOFTWARE renderer\n");
	printk("[wipeout] SMP: arch_num_cpus()=%u  (MP_MAX_NUM_CPUS=%d)\n",
	       (unsigned)arch_num_cpus(), CONFIG_MP_MAX_NUM_CPUS);

	pizza_display = DEVICE_DT_GET(DT_CHOSEN(zephyr_display));
	if (!device_is_ready(pizza_display)) {
		printk("[wipeout] display device not ready -- HDMI not connected?\n");
		return -ENODEV;
	}

	struct display_capabilities caps;

	display_get_capabilities(pizza_display, &caps);
	pizza_display_ready = 1;
	printk("[wipeout] display %ux%u (HVS virt) fmt=0x%x\n",
	       caps.x_resolution, caps.y_resolution,
	       (unsigned)caps.current_pixel_format);

	if (caps.x_resolution != PIZZA_W || caps.y_resolution != PIZZA_H) {
		printk("[wipeout] WARNING: display reports %ux%u, expected %ux%u "
		       "(check render-width/render-height in overlay)\n",
		       caps.x_resolution, caps.y_resolution, PIZZA_W, PIZZA_H);
	}

	/* Spin the band-worker pool now (even on UP -- it's harmless and
	 * lets the render loop assume gfx_parallel_run is available).
	 * M5 benchmark switches between serial / parallel via the shell.
	 */
	extern void gfx_parallel_init(int nbands);
	gfx_parallel_init(4);

	k_thread_create(&pizza_game_thread, pizza_game_stack, GAME_STACK_SIZE,
			pizza_game_loop, NULL, NULL, NULL,
			K_PRIO_PREEMPT(1), 0, K_NO_WAIT);
	k_thread_name_set(&pizza_game_thread, "wipeout_game");

	/* main() returns; the game thread + shell continue. */
	return 0;
}
```

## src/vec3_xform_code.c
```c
#include "vec3_xform_code.h"

#ifdef __cplusplus
extern "C" {
#endif

#ifdef _MSC_VER
__declspec(align(8))
#elif defined(__GNUC__)
__attribute__((aligned(8)))
#endif
uint32_t vec3_xform_code[234] = {
0x15827d80, 0x10020027,
0x15827d80, 0x10020067,
0x15827d80, 0x100200a7,
0x15827d80, 0x100200e7,
0x15827d80, 0x10021027,
0x15827d80, 0x10021067,
0x15827d80, 0x100210a7,
0x15827d80, 0x100210e7,
0x15827d80, 0x10021127,
0x15827d80, 0x10021167,
0x15827d80, 0x100211a7,
0x15827d80, 0x100211e7,
0x15827d80, 0x10021227,
0x15827d80, 0x10021267,
0x15827d80, 0x100212a7,
0x15827d80, 0x100212e7,
0x15827d80, 0x10021327,
0x15827d80, 0x10021367,
0x15827d80, 0x100213a7,
0x15827d80, 0x100213e7,
0x15027d80, 0x10020127,
0x00000040, 0xe0021427,
0x81011000, 0xe00208a7,
0x11104dc0, 0xd00208e7,
0x0c9e74c0, 0x10020c67,
0x15067d80, 0x10020ca7,
0x15ca7d80, 0x100009e7,
0x00101a00, 0xe00208a7,
0x0c127580, 0x10020c67,
0x15c27d80, 0x10020167,
0x0c050dc0, 0x10020067,
0x81011000, 0xe00208a7,
0x11104dc0, 0xd00208e7,
0x0c9e74c0, 0x10020c67,
0x15067d80, 0x10020ca7,
0x15ca7d80, 0x100009e7,
0x00101a00, 0xe00208a7,
0x0c127580, 0x10020c67,
0x15c27d80, 0x100201a7,
0x0c050dc0, 0x10020067,
0x81011000, 0xe00208a7,
0x11104dc0, 0xd00208e7,
0x0c9e74c0, 0x10020c67,
0x15067d80, 0x10020ca7,
0x15ca7d80, 0x100009e7,
0x00101a00, 0xe00208a7,
0x0c127580, 0x10020c67,
0x15c27d80, 0x100201e7,
0x0c050dc0, 0x10020067,
0x2014003e, 0x100049e0,
0x2018403e, 0x100049e1,
0x019e7040, 0x10020827,
0x201c803e, 0x100049e1,
0x019e7040, 0x10020827,
0x019cc1c0, 0x10020227,
0x2014103e, 0x100049e0,
0x2018503e, 0x100049e1,
0x019e7040, 0x10020827,
0x201c903e, 0x100049e1,
0x019e7040, 0x10020827,
0x019cd1c0, 0x10020267,
0x2014203e, 0x100049e0,
0x2018603e, 0x100049e1,
0x019e7040, 0x10020827,
0x201ca03e, 0x100049e1,
0x019e7040, 0x10020827,
0x019ce1c0, 0x100202a7,
0x2014303e, 0x100049e0,
0x2018703e, 0x100049e1,
0x019e7040, 0x10020827,
0x201cb03e, 0x100049e1,
0x019e7040, 0x10020827,
0x019cf1c0, 0x100202e7,
0x00101a00, 0xe00208a7,
0x0c127580, 0x10021c67,
0x15227d80, 0x10020c27,
0x80904000, 0xe00208a7,
0x11107dc0, 0xd00208e7,
0x0c9e74c0, 0x10021c67,
0x150a7d80, 0x10021ca7,
0x159f2fc0, 0x100009e7,
0x0c090dc0, 0x100200a7,
0x00101a00, 0xe00208a7,
0x0c127580, 0x10021c67,
0x15267d80, 0x10020c27,
0x80904000, 0xe00208a7,
0x11107dc0, 0xd00208e7,
0x0c9e74c0, 0x10021c67,
0x150a7d80, 0x10021ca7,
0x159f2fc0, 0x100009e7,
0x0c090dc0, 0x100200a7,
0x00101a00, 0xe00208a7,
0x0c127580, 0x10021c67,
0x152a7d80, 0x10020c27,
0x80904000, 0xe00208a7,
0x11107dc0, 0xd00208e7,
0x0c9e74c0, 0x10021c67,
0x150a7d80, 0x10021ca7,
0x159f2fc0, 0x100009e7,
0x0c090dc0, 0x100200a7,
0x00101a00, 0xe00208a7,
0x0c127580, 0x10021c67,
0x152e7d80, 0x10020c27,
0x80904000, 0xe00208a7,
0x11107dc0, 0xd00208e7,
0x0c9e74c0, 0x10021c67,
0x150a7d80, 0x10021ca7,
0x159f2fc0, 0x100009e7,
0x0c090dc0, 0x100200a7,
0x0d0c1dc0, 0xd00220e7,
0xfffffd20, 0xf01809e7,
0x009e7000, 0x100009e7,
0x009e7000, 0x100009e7,
0x009e7000, 0x100009e7,
0x009e7000, 0x300009e7,
0x009e7000, 0x100009e7,
0x009e7000, 0x100009e7
};
#ifdef __HIGHC__
#pragma Align_to(8, vec3_xform_code)
#ifdef __cplusplus
}
#endif
#endif
```

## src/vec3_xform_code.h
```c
#ifndef vec3_xform_code_H
#define vec3_xform_code_H

#include <inttypes.h>

#ifdef __cplusplus
extern "C" {
#endif

extern uint32_t vec3_xform_code[234];


#ifdef __cplusplus
}
#endif
#endif
```
